# EFR32BG22C224F512GM40 register map
Vendor: Silicon Labs; Series: EFR32; File version: C
Registers are 32-bit, read-write, reset 0x0 unless marked. A register's access mark holds for its fields unless they carry their own. Offsets are from the block's base; [hi:lo] are bit positions; {n}, {i} and the like mark numbered series.

## SMU_S — SMU_S Registers
Base 0x44008000
Same registers: SMU_NS 0x54008000
0x00 IPVERSION ro reset 0x1 — The read only IPVERSION field gives the version for this module. There may be minor software changes required for modules with different values of IPVERSION.
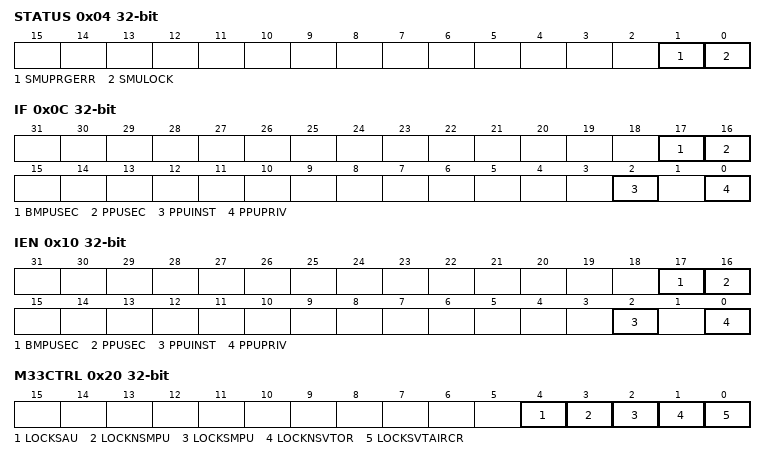
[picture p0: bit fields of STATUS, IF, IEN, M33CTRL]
0x04 STATUS ro — Read to get SMU status.
  [1] SMUPRGERR — SMU Programming Error
  [0] SMULOCK
    0=UNLOCKED (SMULOCK is Unlocked); 1=LOCKED (SMULOCK is Locked)
0x08 LOCK wo — Access to Lock/unlock the SMU Configuration.
  [23:0] SMULOCKKEY
    0xACCE55=UNLOCK (Unlocks Registers)
0x0C IF — Read to get status of SMU interrupts.
  [17] BMPUSEC — BMPU Security Interrupt Flag
  [16] PPUSEC — PPU Security Interrupt Flag
  [2] PPUINST — PPU Instruction Interrupt Flag
  [0] PPUPRIV — PPU Privilege Interrupt Flag
0x10 IEN — Write to Enable/Disable SMU interrupts.
  [17] BMPUSEC — BMPU Security Interrupt Enable
  [16] PPUSEC — PPU Security Interrupt Enable
  [2] PPUINST — PPU Instruction Interrupt Enable
  [0] PPUPRIV — PPU Privilege Interrupt Enable
0x20 M33CTRL — Holds the M33 control settings.
  [4] LOCKSAU — LOCKSAU control of M33 CPU
  [3] LOCKNSMPU — LOCKNSMPU control of M33 CPU
  [2] LOCKSMPU — LOCKSMPU control of M33 CPU
  [1] LOCKNSVTOR — LOCKNSVTOR control of M33 CPU
  [0] LOCKSVTAIRCR — LOCKSVTAIRCR control of M33 CPU
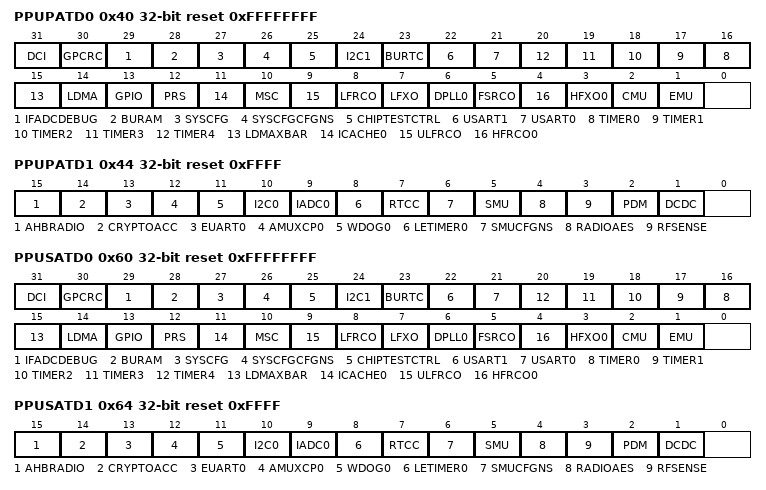
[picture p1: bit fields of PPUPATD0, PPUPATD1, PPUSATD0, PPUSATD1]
0x40 PPUPATD0 reset 0xFFFFFFFF — Set peripheral bits to 1 to mark as privileged access only.
  [31] DCI — DCI Privileged Access
  [30] GPCRC — GPCRC Privileged Access
  [29] IFADCDEBUG — IFADCDEBUG Privileged Access
  [28] BURAM — BURAM Privileged Access
  [27] SYSCFG — SYSCFG Privileged Access
  [26] SYSCFGCFGNS — SYSCFGCFGNS Privileged Access
  [25] CHIPTESTCTRL — CHIPTESTCTRL Privileged Access
  [24] I2C1 — I2C1 Privileged Access
  [23] BURTC — BURTC Privileged Access
  [22] USART1 — USART1 Privileged Access
  [21] USART0 — USART0 Privileged Access
  [n+16] TIMER{n} (n=0..4) — TIMER{n} Privileged Access
  [15] LDMAXBAR — LDMAXBAR Privileged Access
  [14] LDMA — LDMA Privileged Access
  [13] GPIO — GPIO Privileged Access
  [12] PRS — PRS Privileged Access
  [11] ICACHE0 — ICACHE0 Privileged Access
  [10] MSC — MSC Privileged Access
  [9] ULFRCO — ULFRCO Privileged Access
  [8] LFRCO — LFRCO Privileged Access
  [7] LFXO — LFXO Privileged Access
  [6] DPLL0 — DPLL0 Privileged Access
  [5] FSRCO — FSRCO Privileged Access
  [4] HFRCO0 — HFRCO0 Privileged Access
  [3] HFXO0 — HFXO0 Privileged Access
  [2] CMU — CMU Privileged Access
  [1] EMU — EMU Privileged Access
0x44 PPUPATD1 reset 0xFFFF — Set peripheral bits to 1 to mark as privileged access only.
  [15] AHBRADIO — AHBRADIO Privileged Access
  [14] CRYPTOACC — CRYPTOACC Privileged Access
  [13] EUART0 — EUART0 Privileged Access
  [12] AMUXCP0 — AMUXCP0 Privileged Access
  [11] WDOG0 — WDOG0 Privileged Access
  [10] I2C0 — I2C0 Privileged Access
  [9] IADC0 — IADC0 Privileged Access
  [8] LETIMER0 — LETIMER0 Privileged Access
  [7] RTCC — RTCC Privileged Access
  [6] SMUCFGNS — SMUCFGNS Privileged Access
  [5] SMU — SMU Privileged Access
  [4] RADIOAES — RADIOAES Privileged Access
  [3] RFSENSE — RFSENSE Privileged Access
  [2] PDM — PDM Privileged Access
  [1] DCDC — DCDC Privileged Access
0x60 PPUSATD0 reset 0xFFFFFFFF — Set peripheral bits to 1 to mark as secure access only.
  [31] DCI — DCI Secure Access
  [30] GPCRC — GPCRC Secure Access
  [29] IFADCDEBUG — IFADCDEBUG Secure Access
  [28] BURAM — BURAM Secure Access
  [27] SYSCFG — SYSCFG Secure Access
  [26] SYSCFGCFGNS — SYSCFGCFGNS Secure Access
  [25] CHIPTESTCTRL — CHIPTESTCTRL Secure Access
  [24] I2C1 — I2C1 Secure Access
  [23] BURTC — BURTC Secure Access
  [22] USART1 — USART1 Secure Access
  [21] USART0 — USART0 Secure Access
  [n+16] TIMER{n} (n=0..4) — TIMER{n} Secure Access
  [15] LDMAXBAR — LDMAXBAR Secure Access
  [14] LDMA — LDMA Secure Access
  [13] GPIO — GPIO Secure Access
  [12] PRS — PRS Secure Access
  [11] ICACHE0 — ICACHE0 Secure Access
  [10] MSC — MSC Secure Access
  [9] ULFRCO — ULFRCO Secure Access
  [8] LFRCO — LFRCO Secure Access
  [7] LFXO — LFXO Secure Access
  [6] DPLL0 — DPLL0 Secure Access
  [5] FSRCO — FSRCO Secure Access
  [4] HFRCO0 — HFRCO0 Secure Access
  [3] HFXO0 — HFXO0 Secure Access
  [2] CMU — CMU Secure Access
  [1] EMU — EMU Secure Access
0x64 PPUSATD1 reset 0xFFFF — Set peripheral bits to 1 to mark as secure access only.
  [15] AHBRADIO — AHBRADIO Secure Access
  [14] CRYPTOACC — CRYPTOACC Secure Access
  [13] EUART0 — EUART0 Secure Access
  [12] AMUXCP0 — AMUXCP0 Secure Access
  [11] WDOG0 — WDOG0 Secure Access
  [10] I2C0 — I2C0 Secure Access
  [9] IADC0 — IADC0 Secure Access
  [8] LETIMER0 — LETIMER0 Secure Access
  [7] RTCC — RTCC Secure Access
  [6] SMUCFGNS — SMUCFGNS Secure Access
  [5] SMU — SMU Secure Access
  [4] RADIOAES — RADIOAES Secure Access
  [3] RFSENSE — RFSENSE Secure Access
  [2] PDM — PDM Secure Access
  [1] DCDC — DCDC Secure Access
0x140 PPUFS ro — Read to get fault status of SMU.
  [7:0] PPUFSPERIPHID — Peripheral ID
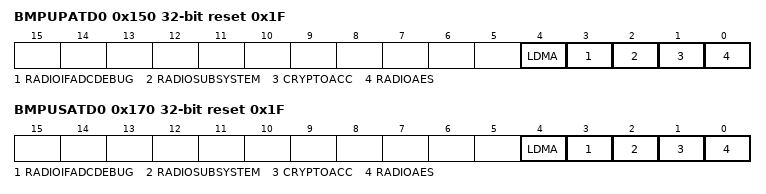
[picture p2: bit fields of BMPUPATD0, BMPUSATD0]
0x150 BMPUPATD0 reset 0x1F — Set master bits to 1 to mark as a privileged master.
  [4] LDMA — MCU LDMA privileged mode
  [3] RADIOIFADCDEBUG — RADIO IFADC debug privileged mode
  [2] RADIOSUBSYSTEM — RADIO subsystem masters privileged mode
  [1] CRYPTOACC — CRYPTOACC DMA privileged mode
  [0] RADIOAES — RADIO AES DMA privileged mode
0x170 BMPUSATD0 reset 0x1F — Set master bits to 1 to mark as a secure master.
  [4] LDMA — MCU LDMA secure mode
  [3] RADIOIFADCDEBUG — RADIO IFADC debug secure mode
  [2] RADIOSUBSYSTEM — RADIO subsystem masters secure mode
  [1] CRYPTOACC — CRYPTOACC DMA secure mode
  [0] RADIOAES — RADIOAES DMA secure mode
0x250 BMPUFS ro — Read to get status about the master that triggered a fault.
  [7:0] BMPUFSMASTERID — Master ID
0x254 BMPUFSADDR ro — Read to get the access address that triggered a fault.
  [31:0] BMPUFSADDR — Fault Address
0x260 ESAURTYPES0 — Write to specify if a region is secure or non-secure.
  [12] ESAUR3NS — Region 3 Non-Secure Type
0x264 ESAURTYPES1 — Write to specify if a region is secure or non-secure.
  [12] ESAUR11NS — Region 11 Non-Secure Type
0x270 ESAUMRB01 reset 0x2000000 — Specify the boundary between regions 0 and 1.
  [27:12] ESAUMRB01 — Moveable Region Boundary 0-1
0x274 ESAUMRB12 reset 0x4000000 — Specify the boundary between regions 1 and 2.
  [27:12] ESAUMRB12 — Moveable Region Boundary 1-2
0x280 ESAUMRB45 reset 0x2000000 — Specify the boundary between regions 4 and 5.
  [27:12] ESAUMRB45 — Moveable Region Boundary 4-5
0x284 ESAUMRB56 reset 0x4000000 — Specify the boundary between regions 5 and 6.
  [27:12] ESAUMRB56 — Moveable Region Boundary 5-6
